# SAMA7G54D4G device description
Architecture: CORTEX-A7; Family: SAMA; Series: SAMA7G
Registers are 32-bit, read-write, reset 0x0 unless marked. A register's access mark holds for its fields unless they carry their own. Offsets are from the block's base; [hi:lo] are bit positions; {n}, {i} and the like mark numbered series.

## TZAESB — TrustZone Advanced Encryption Standard Bridge
Instances: TZAESBNS 0xE0820000, TZAESBS 0xE0824000
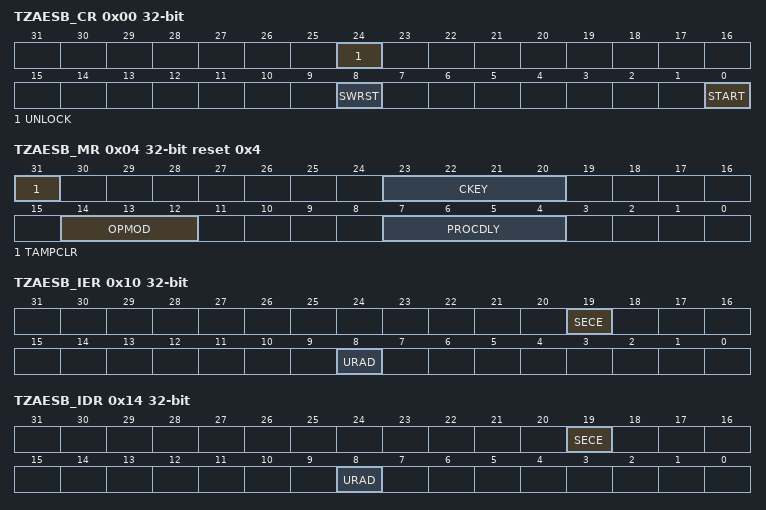
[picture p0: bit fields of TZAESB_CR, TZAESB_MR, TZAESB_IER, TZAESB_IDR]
0x00 TZAESB_CR wo reset not defined — Control Register
  [24] UNLOCK — Unlock Processing
    0=No effect; 1=Unlocks the processing in case of abnormal event detection if TZAESB_WPMR.ACTION > 0
  [8] SWRST — Software Reset
    0=No effect; 1=Resets the TZAESB. A software triggered hardware reset of the TZAESB interface is performed.
  [0] START — Start Processing
    0=No effect; 1=Starts manual encryption/decryption process
0x04 TZAESB_MR reset 0x4 — Mode Register
  [31] TAMPCLR — Tamper Clear Enable
    0=A tamper detection event has no effect on the TZAESB_KEYWRx key; 1=A tamper detection event immediately clears the TZAESB_KEYWRx key
  [23:20] CKEY — Key
    14=PASSWD (Must be written with 0xE the first time that TZAESB_MR is programmed. For subsequent programming of TZAESB_MR, any value can be written, including that of 0xE. Always reads as 0.)
  [14:12] OPMOD — Operating Mode
    4=CTR (Counter mode (16-bit internal counter))
  [7:4] PROCDLY — Processing Delay
0x10 TZAESB_IER wo reset not defined (atomic set of TZAESB_IMR) — Interrupt Enable Register
  [19] SECE — Security and/or Safety Event
  [8] URAD — Unspecified Register Access Detection Interrupt Enable
0x14 TZAESB_IDR wo reset not defined (atomic clear of TZAESB_IMR) — Interrupt Disable Register
  [19] SECE — Security and/or Safety Event
  [8] URAD — Unspecified Register Access Detection Interrupt Disable
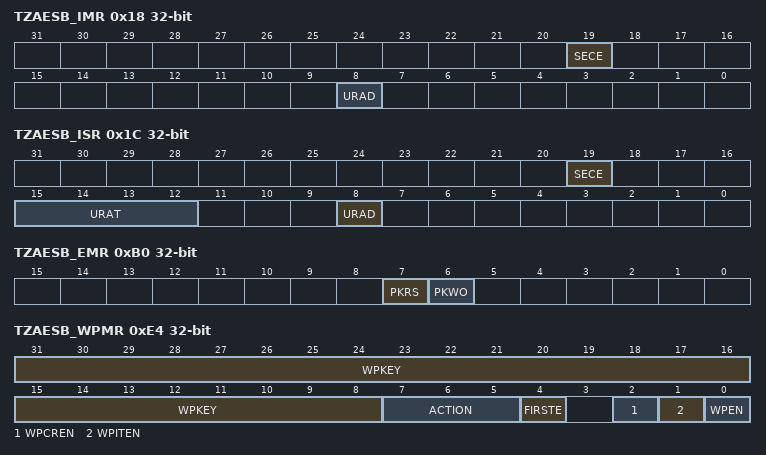
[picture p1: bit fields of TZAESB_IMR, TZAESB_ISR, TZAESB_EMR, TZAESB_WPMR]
0x18 TZAESB_IMR ro — Interrupt Mask Register
  [19] SECE — Security and/or Safety Event
  [8] URAD — Unspecified Register Access Detection Interrupt Mask
0x1C TZAESB_ISR ro — Interrupt Status Register
  [19] SECE — Security and/or Safety Event
    0=There is no security report in TZAESB_WPSR; 1=One security flag is set in TZAESB_WPSR
  [15:12] URAT — Unspecified Register Access
    0=IDR_WR_PROCESSING (Input Data register written during the data processing); 1=ODR_RD_PROCESSING (Output Data register read during the data processing); 2=MR_WR_PROCESSING (Mode register written during the data processing); 3=ODR_RD_SUBKGEN (Output Data register read during the sub-keys generation); 4=MR_WR_SUBKGEN (Mode register written during the sub-keys generation); 5=WOR_RD_ACCESS (Write-only register read access)
  [8] URAD — Unspecified Register Access Detection Status
    0=No unspecified register access has been detected since the last SWRST; 1=At least one unspecified register access has been detected since the last SWRST
{0x20+4i} TZAESB_KEYWR[{i}] (i=0..3) wo reset not defined — Key Word Register x
  [31:0] KEYW — Key Word
{0x60+4i} TZAESB_IVR[{i}] (i=0..3) wo reset not defined — Initialization Vector Register x
  [31:0] IV — Initialization Vector
0xB0 TZAESB_EMR — Extended Mode Register
  [7] PKRS — Private Key Internal Register Select
    0=The key used by the TZAESB is in the TZAESB_KEYWRx; 1=The key used by the TZAESB is in the Private Key internal registers written through the Private Key bus
  [6] PKWO — Private Key Write Once
    0=The Private Key internal registers can be written multiple times through the Private Key bus; 1=The Private Key internal registers can be written only once through the Private Key bus until hardware reset
0xE4 TZAESB_WPMR — Write Protection Mode Register
  [31:8] WPKEY — Write Protection Key
    0x414553=PASSWD (Writing any other value in this field aborts the write operation of the WPEN, WPITEN and WPCREN bits. Always reads as 0.)
  [7:5] ACTION — Action on Abnormal Event Detection
    0=REPORT_ONLY (No action (stop or clear key) is performed when one of PKRPVS, WPVS, CGD, SEQE, or SWE flags is set.); 1=LOCK_PKRPVS_WPVS_SWE (If a processing is in progress when the TZAESB_WPSR.PKRPVS/WPVS/SWE event detection occurs, the current processing is ended normally but no other processing is started while a TZAESB_CR.UNLOCK command is issued.); 2=LOCK_CGD_SEQE (If a processing is in progress when the TZAESB_WPSR.CGD/SEQE event detection occurs, the current processing is ended normally but no other processing is started while a TZAESB_CR.UNLOCK command is issued.); 3=LOCK_ANY_EV (If a processing is in progress when the TZAESB_WPSR.PKRPVS/WPVS/CGD/SEQE/SWE events detection occurs, the current processing is ended normally but no other processing is started while a TZAESB_CR.UNLOCK command is issued.); 4=CLEAR_PKRPVS_WPVS_SWE (If a processing is in progress when the TZAESB_WPSR.PKRPVS/WPVS/SWE events detection occurs, the current processing is ended normally but no other processing is started while a TZAESB_CR.UNLOCK command is issued. Moreover, the TZAESB_KEYWRx key is immediately cleared.); 5=CLEAR_CGD_SEQE (If a processing is in progress when the TZAESB_WPSR.CGD/SEQE events detection occurs, the current processing is ended normally but no other processing is started while a TZAESB_CR.UNLOCK command is issued. Moreover, the TZAESB_KEYWRx key is immediately cleared.); 6=CLEAR_ANY_EV (If a processing is in progress when the TZAESB_WPSR.PKRPVS/WPVS/CGD/SEQE/SWE events detection occurs, the current processing is ended normally but no other processing is started while a TZAESB_CR.UNLOCK command is issued. Moreover, the TZAESB_KEYWRx key is immediately cleared.)
  [4] FIRSTE — First Error Report Enable
    0=The last write protection violation source is reported in TZAESB_WPSR.WPVSRC and the last software control error type is reported in TZAESB_WPSR.SWETYP. The TZAESB_ISR.SECE flag is set at the first error occurrence within a series.; 1=Only the first write protection violation source is reported in TZAESB_WPSR.WPVSRC and only the first software control error type is reported in TZAESB_WPSR.SWETYP. The TZAESB_ISR.SECE flag is set at the first error occurrence within a series.
  [2] WPCREN — Write Protection Control Enable
    0=Disables the write protection on control register if WPKEY corresponds to 0x414553 ("AES" in ASCII); 1=Enables the write protection on control register if WPKEY corresponds to 0x414553 ("AES" in ASCII)
  [1] WPITEN — Write Protection Interruption Enable
    0=Disables the write protection on interrupt registers if WPKEY corresponds to 0x414553 ("AES" in ASCII); 1=Enables the write protection on interrupt registers if WPKEY corresponds to 0x414553 ("AES" in ASCII)
  [0] WPEN — Write Protection Configuration Enable
    0=Disables the write protection on configuration registers if WPKEY corresponds to 0x414553 ("AES" in ASCII); 1=Enables the write protection on configuration registers if WPKEY corresponds to 0x414553 ("AES" in ASCII)
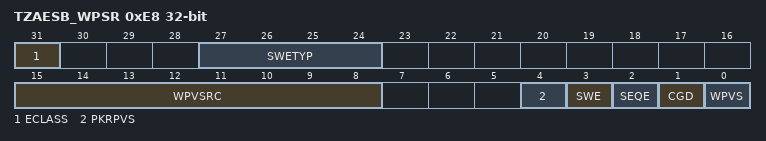
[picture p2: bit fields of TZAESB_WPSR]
0xE8 TZAESB_WPSR ro — Write Protection Status Register
  [31] ECLASS — Software Error Class (cleared on read)
    0=WARNING (An abnormal access that does not affect system functionality); 1=ERROR (An access is performed into key, input data, control registers while the TZAESB is performing an encryption/decryption or a start is request by software or DMA while the key is not fully configured.)
  [27:24] SWETYP — Software Error Type (cleared on read)
    0=READ_WO (A write-only register has been read (Warning).); 1=WRITE_RO (TZAESB is enabled and a write access has been performed on a read-only register (Warning).); 2=UNDEF_RW (Access to an undefined address (Warning).); 3=CTRL_START (Abnormal use of TZAESB_CR.START command when DMA access is configured.); 4=WEIRD_ACTION (A Private Key bus access, key write, init value write, output data read or TZAESB_MR and TZAESB_EMR write has been performed while a process is in progress (abnormal).); 5=INCOMPLETE_KEY (A tentative of start is required while the key is not fully loaded into the TZAESB_KEYWRx registers.)
  [15:8] WPVSRC — Write Protection Violation Source
  [4] PKRPVS — Private Key Internal Register Protection Violation Status (cleared on read)
    0=No Private Key internal register access violation has occurred since the last read of TZAESB_WPSR; 1=A Private Key internal register access violation has occurred since the last read of TZAESB_WPSR
  [3] SWE — Software Control Error (cleared on read)
    0=No software error has occurred since the last read of TZAESB_WPSR; 1=A software error has occurred since the last read of TZAESB_WPSR. The field SWETYP details the type of software error; the associated incorrect software access is reported in the field WPVSRC (if WPVS=0).
  [2] SEQE — Internal Sequencer Error (cleared on read)
    0=No peripheral internal sequencer error has occurred since the last read of TZAESB_WPSR; 1=A peripheral internal sequencer error has occurred since the last read of TZAESB_WPSR. This flag can only be set under abnormal operating conditions.
  [1] CGD — Clock Glitch Detected (cleared on read)
    0=No clock glitch has occurred since the last read of TZAESB_WPSR. Under normal operating conditions, this bit is always cleared.; 1=A clock glitch has occurred since the last read of TZAESB_WPSR. This flag can only be set in case of an abnormal clock signal waveform (glitch).
  [0] WPVS — Write Protection Violation Status (cleared on read)
    0=No write protect violation has occurred since the last read of TZAESB_WPSR; 1=A write protect violation has occurred since the last read of TZAESB_WPSR. The address offset of the violated register is reported into field WPVSRC.
